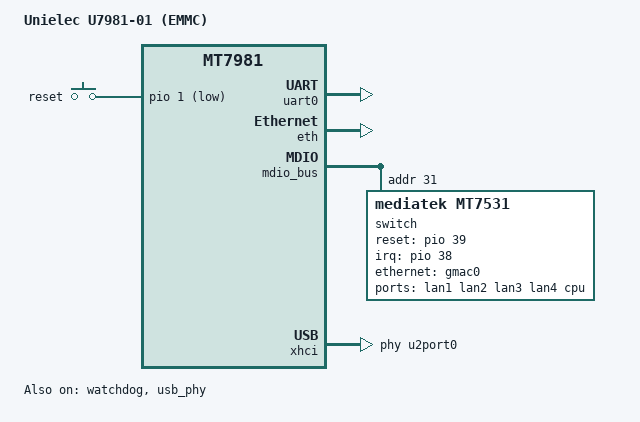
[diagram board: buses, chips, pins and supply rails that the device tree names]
// SPDX-License-Identifier: GPL-2.0-or-later OR MIT
/*
 * Copyright (C) 2023 Allen Zhao <allenzhao@unielecinc.com>
 */

/dts-v1/;
#include "mt7981.dtsi"
/ {
	model = "Unielec U7981-01 (EMMC)";
	compatible = "unielec,u7981-01-emmc", "mediatek,mt7981";

	chosen {
		bootargs = "console=ttyS0,115200n1 loglevel=8  \
				earlycon=uart8250,mmio32,0x11002000 \
				";
	};

	gpio-keys {
		compatible = "gpio-keys";
		reset {
			label = "reset";
			linux,code = <KEY_RESTART>;
			gpios = <&pio 1 GPIO_ACTIVE_LOW>;
		};
	};
};

&uart0 {
	status = "okay";
};

&watchdog {
	status = "okay";
};

&eth {
	pinctrl-names = "default";
	pinctrl-0 = <&mdio_pins &gbe_led0_pins &gbe_led1_pins>;
	status = "okay";

	gmac0: mac@0 {
		/* LAN */
		compatible = "mediatek,eth-mac";
		reg = <0>;
		phy-mode = "2500base-x";

		fixed-link {
			speed = <2500>;
			full-duplex;
			pause;
		};
	};

	gmac1: mac@1 {
		/* WAN */
		compatible = "mediatek,eth-mac";
		reg = <1>;
		phy-mode = "gmii";
		phy-handle = <&int_gbe_phy>;
	};
};

&mdio_bus {
	switch: switch@1f {
		compatible = "mediatek,mt7531";
		reg = <31>;
		reset-gpios = <&pio 39 GPIO_ACTIVE_HIGH>;
		interrupt-controller;
		#interrupt-cells = <1>;
		interrupt-parent = <&pio>;
		interrupts = <38 IRQ_TYPE_LEVEL_HIGH>;
	};
};

&switch {
	ports {
		#address-cells = <1>;
		#size-cells = <0>;

		port@0 {
			reg = <0>;
			label = "lan1";
		};

		port@1 {
			reg = <1>;
			label = "lan2";
		};

		port@2 {
			reg = <2>;
			label = "lan3";
		};

		port@3 {
			reg = <3>;
			label = "lan4";
		};

		port@6 {
			reg = <6>;
			label = "cpu";
			ethernet = <&gmac0>;
			phy-mode = "2500base-x";

			fixed-link {
				speed = <2500>;
				full-duplex;
				pause;
			};
		};
	};
};

&usb_phy {
	status = "okay";
};

&xhci {
	mediatek,u3p-dis-msk = <0x0>;
	phys = <&u2port0 PHY_TYPE_USB2>,
	       <&u3port0 PHY_TYPE_USB3>;
	status = "okay";
};
